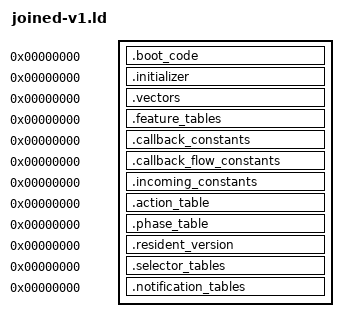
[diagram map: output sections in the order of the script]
OUTPUT_ARCH(riscv)
SECTIONS
{
 .boot_code 0 : SUBALIGN(2) { *(.boot_code)
  *(.text.tsl9_record_state_controls_entry_aad8)
  *(.text.tsl9_selector_notifications_provider_ac78)
  *(.text.tsl9_record_state_controls_block_ac90)
  *(.text.tsl9_record_state_controls_block_ac96)
  *(.text.tsl9_record_state_controls_block_ac9c)
  *(.text.tsl9_record_state_controls_block_aca2)
  *(.text.tsl9_record_state_controls_block_aca8)
  *(.text.tsl9_record_state_controls_block_acb2)
  *(.text.tsl9_record_state_controls_block_acb6)
  *(.text.tsl9_record_state_controls_block_acc0)
  *(.text.tsl9_record_state_controls_block_acc6)
  *(.text.tsl9_record_state_controls_block_acd2)
  *(.text.tsl9_record_state_controls_block_acd6)
  *(.text.tsl9_record_state_controls_block_acd8)
  *(.text.tsl9_record_state_controls_block_ace4)
  *(.text.tsl9_record_state_controls_block_acea)
  *(.text.tsl9_record_state_controls_block_acf6)
  *(.text.tsl9_record_state_controls_block_ad14)
  *(.text.tsl9_record_state_controls_block_ad1a)
  *(.text.tsl9_record_state_controls_block_ad20)
  *(.text.tsl9_record_state_controls_block_ad24)
  *(.text.tsl9_record_state_controls_block_ad36)
  *(.text.tsl9_record_state_controls_block_ad3a)
  *(.text.tsl9_record_state_controls_block_ad3c)
  *(.text.tsl9_record_state_controls_entry_ad48)
  *(.text.tsl9_record_state_controls_block_ad54)
  *(.text.tsl9_record_state_controls_block_ad6c)
  *(.text.tsl9_record_state_controls_block_ad76)
  *(.text.tsl9_record_state_controls_block_ad7a)
  *(.text.tsl9_record_state_controls_block_ad84)
  *(.text.tsl9_record_state_controls_block_ad98)
  *(.text.tsl9_record_state_controls_block_ad9c)
  *(.text.tsl9_record_state_controls_block_ad9e)
  *(.text.tsl9_record_state_controls_block_ada4)
  *(.text.tsl9_record_state_controls_block_adac)
  *(.text.tsl9_record_state_controls_block_adb0)
  *(.text.tsl9_record_state_controls_block_adb2)
  *(.text.tsl9_record_state_controls_block_adb4)
  *(.text.tsl9_record_state_controls_block_adb6)
  *(.text.tsl9_selector_notifications_provider_c364)
  *(.text.tsl9_record_state_controls_block_c37c)
  *(.text.tsl9_record_state_controls_block_c382)
  *(.text.tsl9_record_state_controls_block_c38c)
  *(.text.tsl9_record_state_controls_block_c392)
  *(.text.tsl9_record_state_controls_block_c39c)
  *(.text.tsl9_record_state_controls_block_c3a4)
  *(.text.tsl9_record_dispatch_provider_c3ac)
  *(.text.tsl9_main_services_provider_c3be)
  *(.text.tsl9_feature_external_c3d4)
  *(.text.tsl9_record_state_controls_block_c3ea)
  *(.text.tsl9_record_state_controls_block_c3f6)
  *(.text.tsl9_record_state_controls_block_c404)
  *(.text.tsl9_record_state_controls_block_c40c)
  *(.text.tsl9_record_state_controls_block_c410)
  *(.text.tsl9_record_state_controls_block_c420)
  *(.text.tsl9_record_state_controls_block_c432)
  *(.text.tsl9_record_state_controls_block_c444)
  *(.text.tsl9_record_state_controls_block_c448)
  *(.text.tsl9_record_state_controls_block_c450)
  *(.text.tsl9_record_state_controls_block_c45a)
  *(.text.tsl9_record_state_controls_entry_d50a)
  *(.text.tsl9_record_state_controls_block_d512)
  *(.text.tsl9_record_state_controls_block_d518)
  *(.text.tsl9_record_state_controls_block_d51e)
  *(.text.tsl9_record_state_controls_block_d52c)
  *(.text.tsl9_record_state_controls_block_d536)
  *(.text.tsl9_record_state_controls_entry_d53c)
  *(.text.tsl9_record_state_controls_block_d544)
  *(.text.tsl9_record_state_controls_block_d54a)
  *(.text.tsl9_record_state_controls_block_d54c)
  *(.text.tsl9_record_state_controls_block_d55a)
  *(.text.tsl9_record_state_controls_block_d562)
  *(.text.tsl9_record_state_controls_block_d564)
  *(.text.tsl9_record_state_controls_block_d572)
  *(.text.tsl9_record_state_controls_entry_d578)
  *(.text.tsl9_record_state_controls_block_d588)
  *(.text.tsl9_record_state_controls_block_d5a2)
  *(.text.tsl9_record_state_controls_block_d5a6)
  *(.text.tsl9_record_state_controls_block_d5a8)
  *(.text.tsl9_record_state_controls_block_d5b2)
  *(.text.tsl9_record_state_controls_block_d5b4)
  *(.text.tsl9_record_state_controls_block_d5b6)
  *(.text.tsl9_record_state_controls_block_d5d2)
  *(.text.tsl9_record_state_controls_block_d5d8)
  *(.text.tsl9_record_state_controls_block_d5dc)
  *(.text.tsl9_record_state_controls_block_d5de)
  *(.text.tsl9_record_state_controls_block_d5e6)
  *(.text.tsl9_record_state_controls_block_d5ea)
  *(.text.tsl9_record_state_controls_block_d5f0)
  *(.text.tsl9_record_state_controls_block_d5f4)
  *(.text.tsl9_record_state_controls_block_d5fa)
  *(.text.tsl9_record_state_controls_block_d606)
  *(.text.tsl9_record_state_controls_block_d608)
  *(.text.tsl9_record_state_controls_block_d622)
  *(.text.tsl9_record_state_controls_block_d628)
  *(.text.tsl9_record_state_controls_block_d62a)
  *(.text.tsl9_feature_external_d632)
  *(.text.tsl9_feature_external_d64a)
  *(.text.tsl9_selector_notifications_provider_d662)
  *(.text.tsl9_record_dispatch_provider_d668)
  *(.text.tsl9_record_state_controls_block_d66a)
  *(.text.tsl9_record_state_controls_block_d67e)
  *(.text.tsl9_main_services_provider_d68a)
  *(.text.tsl9_feature_external_d69c)
  *(.text.tsl9_record_state_controls_block_d6e0)
  *(.text.tsl9_record_state_controls_block_d6e8)
  *(.text.tsl9_record_state_controls_block_d6f0)
  *(.text.tsl9_record_state_controls_block_d6f8)
  *(.text.tsl9_record_state_controls_block_d752)
  *(.text.tsl9_selector_notifications_provider_101de)
  *(.text.tsl9_record_state_controls_block_101e8)
  *(.text.tsl9_record_state_controls_block_101ea)
  *(.text.tsl9_record_state_controls_block_101f0)
  *(.text.tsl9_record_state_controls_block_101f6)
  *(.text.tsl9_record_state_controls_block_101fc)
  *(.text.tsl9_record_state_controls_block_1020c)
  *(.text.tsl9_record_state_controls_block_10216)
  *(.text.tsl9_record_state_controls_block_10220)
  *(.text.tsl9_record_state_controls_block_1022e)
  *(.text.tsl9_record_state_controls_block_10238)
  *(.text.tsl9_record_state_controls_block_1023a)
  *(.text.tsl9_record_state_controls_block_1024a)
  *(.text.tsl9_record_state_controls_block_10256)
  *(.text.tsl9_record_state_controls_block_10258)
  *(.text.tsl9_record_state_controls_block_10268)
  *(.text.tsl9_record_state_controls_block_10274)
 }
 .initializer 0 : SUBALIGN(4) { *(.initializer) }
 .vectors 0 : SUBALIGN(4) { *(.vectors) }
 .feature_tables 0 : SUBALIGN(4) { *(.feature_tables) }
 .callback_constants 0 : SUBALIGN(4) { *(.callback_constants) }
 .callback_flow_constants 0 : SUBALIGN(4) { *(.callback_flow_constants) }
 .incoming_constants 0 : SUBALIGN(4) { *(.incoming_constants) }
 .action_table 0 : SUBALIGN(4) { *(.action_table) }
 .phase_table 0 : SUBALIGN(4) { *(.phase_table) }
 .resident_version 0 : SUBALIGN(4) { *(.resident_version) }
 .selector_tables 0 : SUBALIGN(1) {
  *(.rodata.tsl9_feature_state_records_static_data_1a4e4)
  *(.rodata.tsl9_feature_state_records_static_data_1a518)
  *(.rodata.tsl9_feature_state_records_static_data_1a528)
  *(.rodata.tsl9_feature_state_records_static_data_1a538)
 }
 .notification_tables 0 : SUBALIGN(4) {
  *(.rodata.tsl9_selector_notifications_table_1a13c)
  *(.rodata.tsl9_selector_notifications_table_1a150)
  *(.rodata.tsl9_selector_notifications_table_1a1c8)
  *(.rodata.tsl9_selector_notifications_table_1a314)
  *(.rodata.tsl9_selector_notifications_table_1a33c)
 }
 /DISCARD/ : { *(.comment) *(.riscv.attributes) *(.llvm_addrsig) }
}
